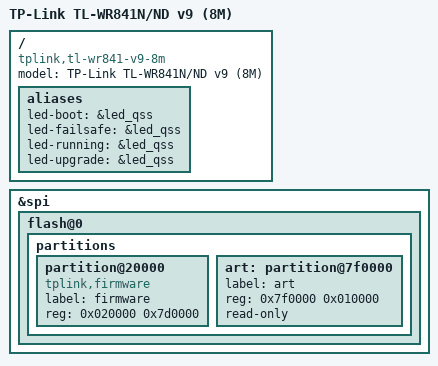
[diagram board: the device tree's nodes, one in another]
// SPDX-License-Identifier: GPL-2.0-or-later OR MIT

#include "qca9533_tplink_tl-wr841-flashmod.dtsi"

/ {
	compatible = "tplink,tl-wr841-v9-8m", "qca,qca9533";
	model = "TP-Link TL-WR841N/ND v9 (8M)";

	aliases {
		led-boot = &led_qss;
		led-failsafe = &led_qss;
		led-running = &led_qss;
		led-upgrade = &led_qss;
	};
};

&spi {
	flash@0 {
		partitions {
			partition@20000 {
				compatible = "tplink,firmware";
				label = "firmware";
				reg = <0x020000 0x7d0000>;
			};

			art: partition@7f0000 {
				label = "art";
				reg = <0x7f0000 0x010000>;
				read-only;
			};
		};
	};
};
